# R7FA4M2AD register map
Vendor: Renesas Electronics Corporation; Series: RA4; File version: 1.20.00
CPU: CM33 r0p4, little endian, MPU, FPU, VTOR, 4 interrupt priority bits, 96 interrupts
Registers are 8-bit, read-write, reset 0x0 unless marked. A register's access mark holds for its fields unless they carry their own. Offsets are from the block's base; [hi:lo] are bit positions.

## IIC0WU — Inter-Integrated Circuit 0 Wake-up Unit
Base 0x4009F014
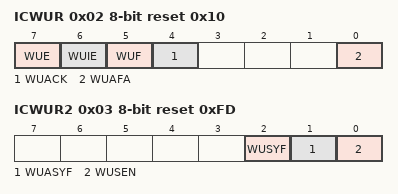
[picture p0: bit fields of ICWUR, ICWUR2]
0x02 ICWUR reset 0x10 — I2C Bus Wakeup Unit Register
  [7] WUE — Wakeup Function Enable
    0=Disable wakeup function; 1=Enable wakeup function
  [6] WUIE — Wakeup Interrupt Request Enable
    0=Disable wakeup interrupt request (IIC0_WUI); 1=Enable wakeup interrupt request (IIC0_WUI)
  [5] WUF — Wakeup Event Occurrence Flag
    0=Slave address not matching during wakeup; 1=Slave address matching during wakeup
  [4] WUACK — ACK Bit for Wakeup Mode
  [0] WUAFA — Wakeup Analog Filter Additional Selection
    0=Do not add the wakeup analog filter; 1=Add the wakeup analog filter
0x03 ICWUR2 reset 0xFD — I2C Bus Wakeup Unit Register 2
  [2] WUSYF ro — Wakeup Function Synchronous Operation Status Flag
    0=IIC asynchronous circuit enable condition; 1=IIC synchronous circuit enable condition
  [1] WUASYF ro — Wakeup Function Asynchronous Operation Status Flag
    0=IIC synchronous circuit enable condition; 1=IIC asynchronous circuit enable condition
  [0] WUSEN — Wakeup Function Synchronous Enable
    0=IIC asynchronous circuit enable; 1=IIC synchronous circuit enable

## CTSU — Capacitive Touch Sensing Unit
Base 0x400D0000
0x00 CTSUCR0 — CTSU Control Register 0
0x01 CTSUCR1 — CTSU Control Register 1
0x02 CTSUSDPRS — CTSU Synchronous Noise Reduction Setting Register
0x03 CTSUSST — CTSU Sensor Stabilization Wait Control Register
0x04 CTSUMCH0 reset 0x1F — CTSU Measurement Channel Register 0
0x05 CTSUMCH1 ro reset 0x1F — CTSU Measurement Channel Register 1
0x06 CTSUCHAC0 — CTSU Channel Enable Control Register 0
0x07 CTSUCHAC1 — CTSU Channel Enable Control Register 1
0x0B CTSUCHTRC0 — CTSU Channel Transmit/Receive Control Register 0
0x0C CTSUCHTRC1 — CTSU Channel Transmit/Receive Control Register 1
0x10 CTSUDCLKC — CTSU High-Pass Noise Reduction Control Register
0x11 CTSUST — CTSU Status Register
0x12 CTSUSSC 16-bit — CTSU High-Pass Noise Reduction Spectrum Diffusion Control Register
  [11:8] CTSUSSDIV — CTSU Spectrum Diffusion Frequency Division Setting
0x14 CTSUSO0 16-bit — CTSU Sensor Offset Register 0
0x16 CTSUSO1 16-bit — CTSU Sensor Offset Register 1
0x18 CTSUSC 16-bit ro — CTSU Sensor Counter
0x1A CTSURC 16-bit ro — CTSU Reference Counter
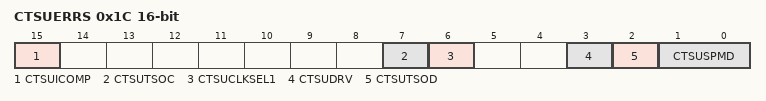
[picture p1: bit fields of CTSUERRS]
0x1C CTSUERRS 16-bit (reset mask 0x7FFF) — CTSU Error Status Register
  [15] CTSUICOMP ro — TSCAP Voltage Error Monitor
    0=Normal TSCAP voltage; 1=Abnormal TSCAP voltage
  [7] CTSUTSOC — Calibration Setting 2
    0=Capacitance measurement mode; 1=Calibration setting 2
  [6] CTSUCLKSEL1 — Calibration Setting 3
    0=Capacitance measurement mode; 1=Calibration setting 3
  [3] CTSUDRV — Calibration Setting 1
    0=Capacitance measurement mode; 1=Calibration setting 1
  [2] CTSUTSOD — TS Pin Fixed Output
    0=Capacitance measurement mode; 1=TS pins are forced to be high or low
  [1:0] CTSUSPMD — Calibration Mode
    0=Capacitance measurement mode; 2=Calibration mode; other=Others (Seting prohibited)
0x20 CTSUTRMR reset not defined — CTSU Reference Current Calibration Register

## TSN — Temperature Sensor
Base 0x400F3000
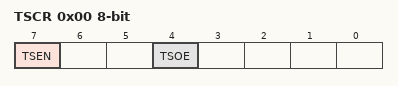
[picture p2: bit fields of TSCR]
0x00 TSCR — Temperature Sensor Control Register
  [7] TSEN — Temperature Sensor Enable
    0=Stop the temperature sensor; 1=Start the temperature sensor
  [4] TSOE — Temperature Sensor Output Enable
    0=Disable output from the temperature sensor to the ADC12; 1=Enable output from the temperature sensor to the ADC12

## CRC — Cyclic Redundancy Check Calculator
Base 0x40108000
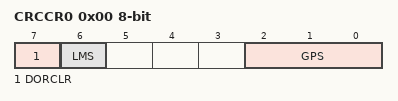
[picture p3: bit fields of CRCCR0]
0x00 CRCCR0 — CRC Control Register 0
  [7] DORCLR wo — CRCDOR/CRCDOR_HA/CRCDOR_BY Register Clear
    0=No effect; 1=Clear the CRCDOR/CRCDOR_HA/CRCDOR_BY register
  [6] LMS — CRC Calculation Switching
    0=Generate CRC code for LSB-first communication; 1=Generate CRC code for MSB-first communication
  [2:0] GPS — CRC Generating Polynomial Switching
    1=8-bit CRC-8 (X8 + X2 + X + 1); 2=16-bit CRC-16 (X16 + X15 + X2 + 1); 3=16-bit CRC-CCITT (X16 + X12 + X5 + 1); 4=32-bit CRC-32 (X32 + X26 + X23 + X22 + X16 + X12 + X11 +X10 + X8 + X7 + X5 + X4 + X2 + X + 1); 5=32-bit CRC-32C (X32 + X28 + X27 + X26 + X25 + X23 + X22 + X20 + X19 + X18 + X14 + X13 + X11 + X10 + X9 + X8 + X6 + 1); other=Others (No calculation is executed)
0x04 CRCDIR 32-bit — CRC Data Input Register
0x04 CRCDIR_BY (alternate view of CRCDIR) — CRC Data Input Register
0x08 CRCDOR 32-bit — CRC Data Output Register
0x08 CRCDOR_HA 16-bit (alternate view of CRCDOR) — CRC Data Output Register
0x08 CRCDOR_BY (alternate view of CRCDOR) — CRC Data Output Register

## Notices in the file
This software is supplied by Renesas Electronics Corporation and is only intended for
use with Renesas products. No other uses are authorized. This software is owned by
Renesas Electronics Corporation and is protected under all applicable laws, including
copyright laws.
THIS SOFTWARE IS PROVIDED "AS IS" AND RENESAS MAKES NO WARRANTIES REGARDING
THIS SOFTWARE, WHETHER EXPRESS, IMPLIED OR STATUTORY, INCLUDING BUT NOT LIMITED TO
WARRANTIES OF MERCHANTABILITY, FITNESS FOR A PARTICULAR PURPOSE AND NON-INFRINGEMENT.
ALL SUCH WARRANTIES ARE EXPRESSLY DISCLAIMED. TO THE MAXIMUM EXTENT PERMITTED NOT
PROHIBITED BY LAW, NEITHER RENESAS ELECTRONICS CORPORATION NOR ANY OF ITS AFFILIATED
COMPANIES SHALL BE LIABLE FOR ANY DIRECT, INDIRECT, SPECIAL, INCIDENTAL OR CONSEQUENTIAL
DAMAGES FOR ANY REASON RELATED TO THIS SOFTWARE, EVEN IF RENESAS OR ITS AFFILIATES HAVE
BEEN ADVISED OF THE POSSIBILITY OF SUCH DAMAGES.
Renesas reserves the right, without notice, to make changes to this software and to
discontinue the availability of this software. By using this software, you agree to
the additional terms and conditions found by accessing the following link:
http://www.renesas.com/disclaimer
